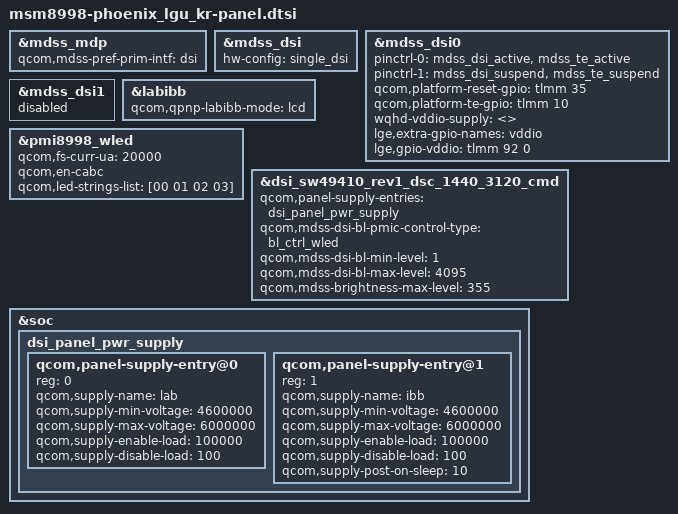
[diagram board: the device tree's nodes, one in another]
/* Copyright (c) 2016, The Linux Foundation. All rights reserved.
 *
 * This program is free software; you can redistribute it and/or modify
 * it under the terms of the GNU General Public License version 2 and
 * only version 2 as published by the Free Software Foundation.
 *
 * This program is distributed in the hope that it will be useful,
 * but WITHOUT ANY WARRANTY; without even the implied warranty of
 * MERCHANTABILITY or FITNESS FOR A PARTICULAR PURPOSE.  See the
 * GNU General Public License for more details.
 */

#include "../msm8998-phoenix-common/dsi-panel-sw49410-dsc-qhd-cmd_overlay.dtsi"

&mdss_mdp {
	qcom,mdss-pref-prim-intf = "dsi";
};

&mdss_dsi {
	hw-config = "single_dsi";
};

&mdss_dsi0 {
	pinctrl-names = "mdss_default", "mdss_sleep";
	pinctrl-0 = <&mdss_dsi_active &mdss_te_active>;
	pinctrl-1 = <&mdss_dsi_suspend &mdss_te_suspend>;
	qcom,platform-reset-gpio = <&tlmm 35 0>;
	qcom,platform-te-gpio = <&tlmm 10 0>;
	wqhd-vddio-supply = <>;
	lge,extra-gpio-names = "vddio";
	lge,gpio-vddio = <&tlmm 92 0>;
/* move to main soc dtb */
//	/delete-property/qcom,null-insertion-enabled;
};

&mdss_dsi1 {
	status = "disabled";
};

/* Start to override parameters in msm-pmi8998.dtsi */
/*
&spmi_bus {
	qcom,pmi8998@3 {
		labibb: qpnp-labibb-regulator {
			status = "ok";
			qcom,qpnp-labibb-mode = "lcd";
		};
		pmi8998_wled: qcom,leds@d800 {
			status = "ok";
			qcom,fs-curr-ua = <20000>;
			qcom,en-cabc;
			qcom,led-strings-list = [00 01 02 03];
		};
	};
};
*/

&labibb {
	status = "ok";
	qcom,qpnp-labibb-mode = "lcd";
};
&pmi8998_wled {
	status = "ok";
	qcom,fs-curr-ua = <20000>;
	qcom,en-cabc;
	qcom,led-strings-list = [00 01 02 03];
/* move to main soc dtb */
//	/delete-property/ qcom,auto-calibration-enable;
};

&dsi_sw49410_rev1_dsc_1440_3120_cmd {
	qcom,panel-supply-entries = <&dsi_panel_pwr_supply>;
	qcom,mdss-dsi-bl-pmic-control-type = "bl_ctrl_wled";
	qcom,mdss-dsi-bl-min-level = <1>;
	qcom,mdss-dsi-bl-max-level = <4095>;
	qcom,mdss-brightness-max-level = <355>;
	/* qcom,cont-splash-enabled; */
	qcom,panel-supply-entries = <&dsi_panel_pwr_supply>;
};

&soc {
	dsi_panel_pwr_supply: dsi_panel_pwr_supply {
		#address-cells = <1>;
		#size-cells = <0>;

		qcom,panel-supply-entry@0 {
			reg = <0>;
			qcom,supply-name = "lab";
			qcom,supply-min-voltage = <4600000>;
			qcom,supply-max-voltage = <6000000>;
			qcom,supply-enable-load = <100000>;
			qcom,supply-disable-load = <100>;
		};

		qcom,panel-supply-entry@1 {
			reg = <1>;
			qcom,supply-name = "ibb";
			qcom,supply-min-voltage = <4600000>;
			qcom,supply-max-voltage = <6000000>;
			qcom,supply-enable-load = <100000>;
			qcom,supply-disable-load = <100>;
			qcom,supply-post-on-sleep = <10>;
		};

	};
};

/* End of overriding parameters in msm8998-mdss-panel.dtsi */
